# STM32WB15_CM4 register map
File version: 1.5
CPU: CM4 r0p1, little endian, MPU, FPU, 4 interrupt priority bits
Registers are 32-bit, read-write, reset 0x0 unless marked. A register's access mark holds for its fields unless they carry their own. Offsets are from the block's base; [hi:lo] are bit positions; {n}, {i} and the like mark numbered series.

## PWR — Power control
Base 0x58000400
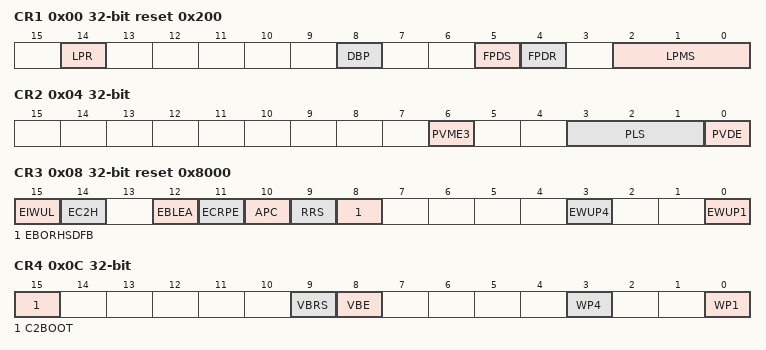
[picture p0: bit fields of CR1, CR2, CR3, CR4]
0x00 CR1 reset 0x200 — Power control register 1
  [14] LPR — Low-power run
  [8] DBP — Disable backup domain write protection
  [5] FPDS — Flash power down mode during LPsSleep for CPU1
  [4] FPDR — Flash power down mode during LPRun for CPU1
  [2:0] LPMS — Low-power mode selection for CPU1
0x04 CR2 — Power control register 2
  [6] PVME3 — Peripheral voltage monitoring 3 enable: VDDA vs. 1.62V
  [3:1] PLS — Power voltage detector level selection
  [0] PVDE — Power voltage detector enable
0x08 CR3 reset 0x8000 — Power control register 3
  [15] EIWUL — Enable internal wakeup line for CPU1
  [14] EC2H — Enable CPU2 Hold interrupt for CPU1
  [12] EBLEA — Enable BLE end of activity interrupt for CPU1
  [11] ECRPE — Enable critical radio phase end of activity interrupt for CPU1
  [10] APC — Apply pull-up and pull-down configuration
  [9] RRS — SRAM2a retention in Standby mode
  [8] EBORHSDFB — Enable BORH and Step Down counverter forced in Bypass interrups for CPU1
  [3] EWUP4 — Enable Wakeup pin WKUP4
  [0] EWUP1 — Enable Wakeup pin WKUP1
0x0C CR4 — Power control register 4
  [15] C2BOOT — BOOT CPU2 after reset or wakeup from Stop or Standby modes
  [9] VBRS — VBAT battery charging resistor selection
  [8] VBE — VBAT battery charging enable
  [3] WP4 — Wakeup pin WKUP4 polarity
  [0] WP1 — Wakeup pin WKUP1 polarity
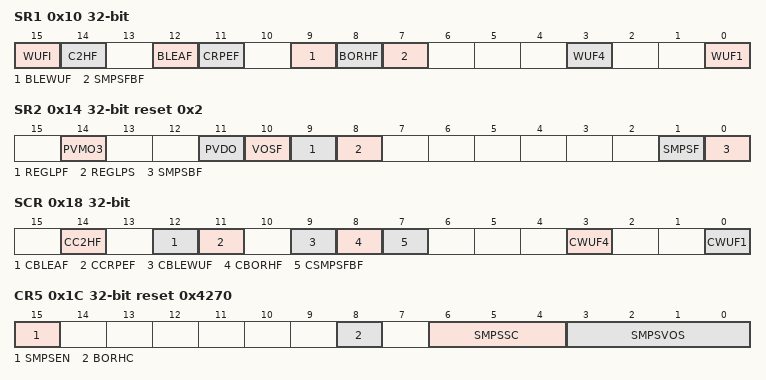
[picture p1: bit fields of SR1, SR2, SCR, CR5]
0x10 SR1 ro — Power status register 1
  [15] WUFI — Internal Wakeup interrupt flag
  [14] C2HF — CPU2 Hold interrupt flag
  [12] BLEAF — BLE end of activity interrupt flag
  [11] CRPEF — Enable critical radio phase end of activity interrupt flag
  [9] BLEWUF — BLE wakeup interrupt flag
  [8] BORHF — BORH interrupt flag
  [7] SMPSFBF — Step Down converter forced in Bypass interrupt flag
  [3] WUF4 — Wakeup flag 4
  [0] WUF1 — Wakeup flag 1
0x14 SR2 ro reset 0x2 — Power status register 2
  [14] PVMO3 — Peripheral voltage monitoring output: VDDA vs. 1.62 V
  [11] PVDO — Power voltage detector output
  [10] VOSF — Voltage scaling flag
  [9] REGLPF — Low-power regulator flag
  [8] REGLPS — Low-power regulator started
  [1] SMPSF — Step Down converter SMPS mode flag
  [0] SMPSBF — Step Down converter Bypass mode flag
0x18 SCR wo — Power status clear register
  [14] CC2HF — Clear CPU2 Hold interrupt flag
  [12] CBLEAF — Clear BLE end of activity interrupt flag
  [11] CCRPEF — Clear critical radio phase end of activity interrupt flag
  [9] CBLEWUF — Clear BLE wakeup interrupt flag
  [8] CBORHF — Clear BORH interrupt flag
  [7] CSMPSFBF — Clear SMPS Step Down converter forced in Bypass interrupt flag
  [3] CWUF4 — Clear wakeup flag 4
  [0] CWUF1 — Clear wakeup flag 1
0x1C CR5 reset 0x4270 — Power control register 5
  [15] SMPSEN — Enable Step Down converter SMPS mode enabled
  [8] BORHC — BORH configuration selection
  [6:4] SMPSSC — Step Down converter supplt startup current selection
  [3:0] SMPSVOS — Step Down converter voltage output scaling
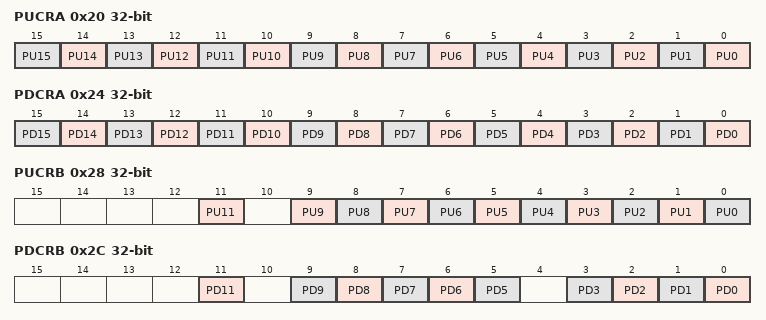
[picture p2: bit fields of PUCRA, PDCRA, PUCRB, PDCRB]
0x20 PUCRA — Power Port A pull-up control register
  [n] PU{n} (n=0..15) — Port A pull-up bit y (y=0..15)
0x24 PDCRA — Power Port A pull-down control register
  [n] PD{n} (n=0..15) — Port A pull-down bit y (y=0..15)
0x28 PUCRB — Power Port B pull-up control register
  [11] PU11 — Port B pull-up bit y (y=0..15)
  [n] PU{n} (n=0..9) — Port B pull-up bit y (y=0..15)
0x2C PDCRB — Power Port B pull-down control register
  [11] PD11 — Port B pull-down bit y (y=0..15)
  [n] PD{n} (n=5..9) — Port B pull-down bit y (y=0..15)
  [n] PD{n} (n=0..3) — Port B pull-down bit y (y=0..15)
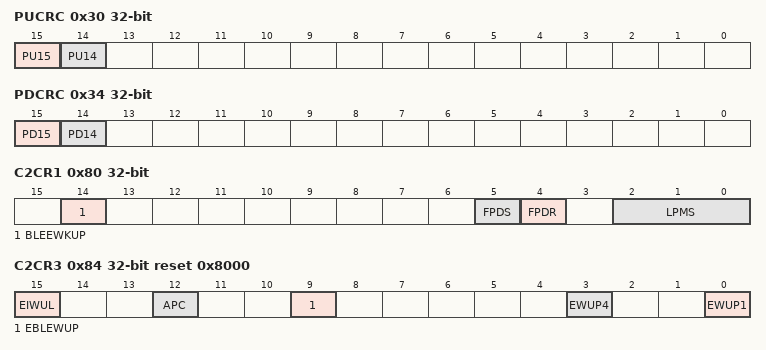
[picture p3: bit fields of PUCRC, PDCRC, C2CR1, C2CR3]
0x30 PUCRC — Power Port C pull-up control register
  [15] PU15 — Port C pull-up bit y (y=0..15)
  [14] PU14 — Port C pull-up bit y (y=0..15)
0x34 PDCRC — Power Port C pull-down control register
  [15] PD15 — Port C pull-down bit y (y=0..15)
  [14] PD14 — Port C pull-down bit y (y=0..15)
0x40 PUCRE — Power Port E pull-up control register
  [4] PU4 — Port E pull-up bit y (y=0..15)
0x44 PDCRE — Power Port E pull-down control register
  [4] PD4 — Port E pull-down bit y (y=0..15)
0x58 PUCRH — Power Port H pull-up control register
  [3] PU3 — Port H pull-up bit y (y=0..1)
0x5C PDCRH — Power Port H pull-down control register
  [3] PD3 — Port H pull-down bit y (y=0..1)
0x80 C2CR1 — CPU2 Power control register 1
  [14] BLEEWKUP — BLE external wakeup signal
  [5] FPDS — Flash power down mode during LPSleep for CPU2
  [4] FPDR — Flash power down mode during LPRun for CPU2
  [2:0] LPMS — Low-power mode selection for CPU2
0x84 C2CR3 reset 0x8000 — CPU2 Power control register 3
  [15] EIWUL — Enable internal wakeup line for CPU2
  [12] APC — Apply pull-up and pull-down configuration for CPU2
  [9] EBLEWUP — Enable BLE host wakeup interrupt for CPU2
  [3] EWUP4 — Enable Wakeup pin WKUP4 for CPU2
  [0] EWUP1 — Enable Wakeup pin WKUP1 for CPU2
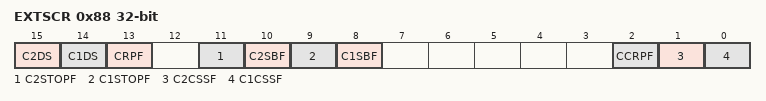
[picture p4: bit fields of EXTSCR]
0x88 EXTSCR access per field — Power status clear register
  [15] C2DS ro — CPU2 deepsleep mode
  [14] C1DS ro — CPU1 deepsleep mode
  [13] CRPF ro — Critical Radio system phase
  [11] C2STOPF ro — System Stop flag for CPU2
  [10] C2SBF ro — System Standby flag for CPU2
  [9] C1STOPF ro — System Stop flag for CPU1
  [8] C1SBF ro — System Standby flag for CPU1
  [2] CCRPF wo — Clear Critical Radio system phase
  [1] C2CSSF wo — Clear CPU2 Stop Standby flags
  [0] C1CSSF wo — Clear CPU1 Stop Standby flags
